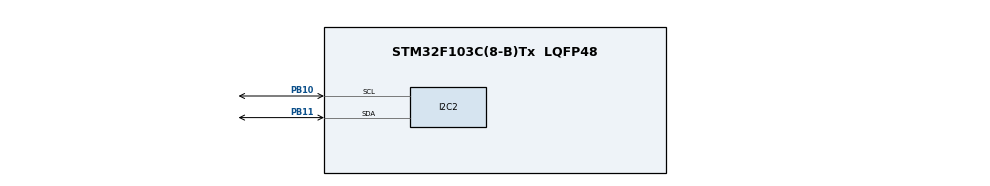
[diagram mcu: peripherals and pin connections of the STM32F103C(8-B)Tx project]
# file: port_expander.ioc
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Mcu.Family=STM32F1
Mcu.Name=STM32F103C(8-B)Tx
Mcu.Package=LQFP48
NVIC.PriorityGroup=NVIC_PRIORITYGROUP_4
PB10.Mode=I2C
PB10.Signal=I2C2_SCL
PB11.Mode=I2C
PB11.Signal=I2C2_SDA
ProjectManager.HeapSize=0x200
ProjectManager.StackSize=0x400
ProjectManager.TargetToolchain=STM32CubeIDE
RCC.APB1Freq_Value=8000000
RCC.APB2Freq_Value=8000000
board=custom

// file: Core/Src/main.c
/* USER CODE BEGIN Header */
/**
  ******************************************************************************
  * @file           : main.c
  * @brief          : Main program body
  ******************************************************************************
  * @attention
  *
  * Copyright (c) 2023 STMicroelectronics.
  * All rights reserved.
  *
  * This software is licensed under terms that can be found in the LICENSE file
  * in the root directory of this software component.
  * If no LICENSE file comes with this software, it is provided AS-IS.
  *
  ******************************************************************************
  */
/* USER CODE END Header */
#include "main.h"

/* USER CODE BEGIN Includes */
#include "dvr_port_exp.h"

/* USER CODE END Includes */

I2C_HandleTypeDef hi2c2;

void SystemClock_Config(void);
static void MX_GPIO_Init(void);
static void MX_I2C2_Init(void);

int main(void)
{

  /* MCU Configuration--------------------------------------------------------*/

  /* Reset of all peripherals, Initializes the Flash interface and the Systick. */
  HAL_Init();

  /* Configure the system clock */
  SystemClock_Config();

  /* Initialize all configured peripherals */
  MX_GPIO_Init();
  MX_I2C2_Init();
  /* USER CODE BEGIN 2 */
  dvr_port_exp_init(0x27);
  /* USER CODE END 2 */

  /* Infinite loop */
  /* USER CODE BEGIN WHILE */
  uint8_t data = 0;
  while (1)
  {
    #ifdef TEST_1
      dvr_port_exp_set_pin(0);
      HAL_Delay(500);
      dvr_port_exp_reset_pin(0);
      HAL_Delay(1000);
      dvr_port_exp_set_port(0xff);
      HAL_Delay(500);
      dvr_port_exp_reset_port(0xff);
      HAL_Delay(1000);
      dvr_port_exp_set_port(PIN_0);
      HAL_Delay(100);
      dvr_port_exp_reset_port(PIN_0);
      HAL_Delay(100);
      dvr_port_exp_set_port(PIN_0);
      HAL_Delay(100);
      dvr_port_exp_reset_port(PIN_0);
      HAL_Delay(100);
      dvr_port_exp_set_port(PIN_0);
      HAL_Delay(100);
      dvr_port_exp_reset_port(PIN_0);
      HAL_Delay(1000);
    #endif // TEST_1

    #ifdef TEST_2
      if (RV_SUCCESS == dvr_port_exp_read_pin(0, &data))
      {
        if (data == true)
        {
          HAL_GPIO_WritePin(GPIOA, GPIO_PIN_2, GPIO_PIN_SET);
          HAL_Delay(1000);
          HAL_GPIO_WritePin(GPIOA, GPIO_PIN_2, GPIO_PIN_RESET);
          HAL_Delay(500);
        }
      }
    #endif // TEST_2

    #define TEST_3
    #ifdef TEST_3
      if (RV_SUCCESS == dvr_port_exp_read_port(PIN_0, &data))
      {
        if (data)
        {
          HAL_GPIO_WritePin(GPIOA, GPIO_PIN_2, GPIO_PIN_SET);
          HAL_Delay(1000);
          HAL_GPIO_WritePin(GPIOA, GPIO_PIN_2, GPIO_PIN_RESET);
          HAL_Delay(500);
        }
      }
    #endif // TEST_3
    /* USER CODE END WHILE */

  }
}

void SystemClock_Config(void)
{
  RCC_OscInitTypeDef RCC_OscInitStruct = {0};
  RCC_ClkInitTypeDef RCC_ClkInitStruct = {0};

  /** Initializes the RCC Oscillators according to the specified parameters
  * in the RCC_OscInitTypeDef structure.
  */
  RCC_OscInitStruct.OscillatorType = RCC_OSCILLATORTYPE_HSI;
  RCC_OscInitStruct.HSIState = RCC_HSI_ON;
  RCC_OscInitStruct.HSICalibrationValue = RCC_HSICALIBRATION_DEFAULT;
  RCC_OscInitStruct.PLL.PLLState = RCC_PLL_NONE;
  if (HAL_RCC_OscConfig(&RCC_OscInitStruct) != HAL_OK)
  {
    Error_Handler();
  }

  /** Initializes the CPU, AHB and APB buses clocks
  */
  RCC_ClkInitStruct.ClockType = RCC_CLOCKTYPE_HCLK|RCC_CLOCKTYPE_SYSCLK
                              |RCC_CLOCKTYPE_PCLK1|RCC_CLOCKTYPE_PCLK2;
  RCC_ClkInitStruct.SYSCLKSource = RCC_SYSCLKSOURCE_HSI;
  RCC_ClkInitStruct.AHBCLKDivider = RCC_SYSCLK_DIV1;
  RCC_ClkInitStruct.APB1CLKDivider = RCC_HCLK_DIV1;
  RCC_ClkInitStruct.APB2CLKDivider = RCC_HCLK_DIV1;

  if (HAL_RCC_ClockConfig(&RCC_ClkInitStruct, FLASH_LATENCY_0) != HAL_OK)
  {
    Error_Handler();
  }
}

static void MX_I2C2_Init(void)
{

  hi2c2.Instance = I2C2;
  hi2c2.Init.ClockSpeed = 100000;
  hi2c2.Init.DutyCycle = I2C_DUTYCYCLE_2;
  hi2c2.Init.OwnAddress1 = 0;
  hi2c2.Init.AddressingMode = I2C_ADDRESSINGMODE_7BIT;
  hi2c2.Init.DualAddressMode = I2C_DUALADDRESS_DISABLE;
  hi2c2.Init.OwnAddress2 = 0;
  hi2c2.Init.GeneralCallMode = I2C_GENERALCALL_DISABLE;
  hi2c2.Init.NoStretchMode = I2C_NOSTRETCH_DISABLE;
  if (HAL_I2C_Init(&hi2c2) != HAL_OK)
  {
    Error_Handler();
  }

}

static void MX_GPIO_Init(void)
{
  GPIO_InitTypeDef GPIO_InitStruct = {0};

  /* GPIO Ports Clock Enable */
  __HAL_RCC_GPIOA_CLK_ENABLE();
  __HAL_RCC_GPIOB_CLK_ENABLE();

  /*Configure GPIO pin Output Level */
  HAL_GPIO_WritePin(GPIOA, GPIO_PIN_2, GPIO_PIN_RESET);

  /*Configure GPIO pin : PA2 */
  GPIO_InitStruct.Pin = GPIO_PIN_2;
  GPIO_InitStruct.Mode = GPIO_MODE_OUTPUT_PP;
  GPIO_InitStruct.Pull = GPIO_NOPULL;
  GPIO_InitStruct.Speed = GPIO_SPEED_FREQ_LOW;
  HAL_GPIO_Init(GPIOA, &GPIO_InitStruct);

}

/* USER CODE BEGIN 4 */

I2C_HandleTypeDef *get_i2c_handle()
{
  return &hi2c2;
}

/* USER CODE END 4 */

void Error_Handler(void)
{
  __disable_irq();
  while (1)
  {
  }
}
